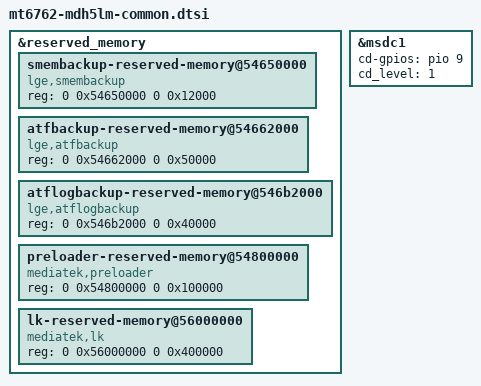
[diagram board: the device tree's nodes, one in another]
/*
 * LG Electronics MT6765 HDK common device tree source
 *
 * Copyright (c) 2019 LG Electronics Co., Ltd.
 *              http://www.lge.com
 *
 */

&reserved_memory {
    #address-cells = <2>;
    #size-cells = <2>;
    smembackup-reserved-memory@54650000 {
        compatible = "lge,smembackup";
        reg = <0 0x54650000 0 0x12000>;
    };

    atfbackup-reserved-memory@54662000 {
        compatible = "lge,atfbackup";
        reg = <0 0x54662000 0 0x50000>;
    };

    atflogbackup-reserved-memory@546b2000 {
        compatible = "lge,atflogbackup";
        reg = <0 0x546b2000 0 0x40000>;
    };

    preloader-reserved-memory@54800000 {
        compatible = "mediatek,preloader";
        reg = <0 0x54800000 0 0x100000>;
    };

    lk-reserved-memory@56000000 {
        compatible = "mediatek,lk";
        reg = <0 0x56000000 0 0x400000>;
    };
};

&msdc1 {
    cd-gpios = <&pio 9 0>;
    cd_level = /bits/ 8 <1>;
};
